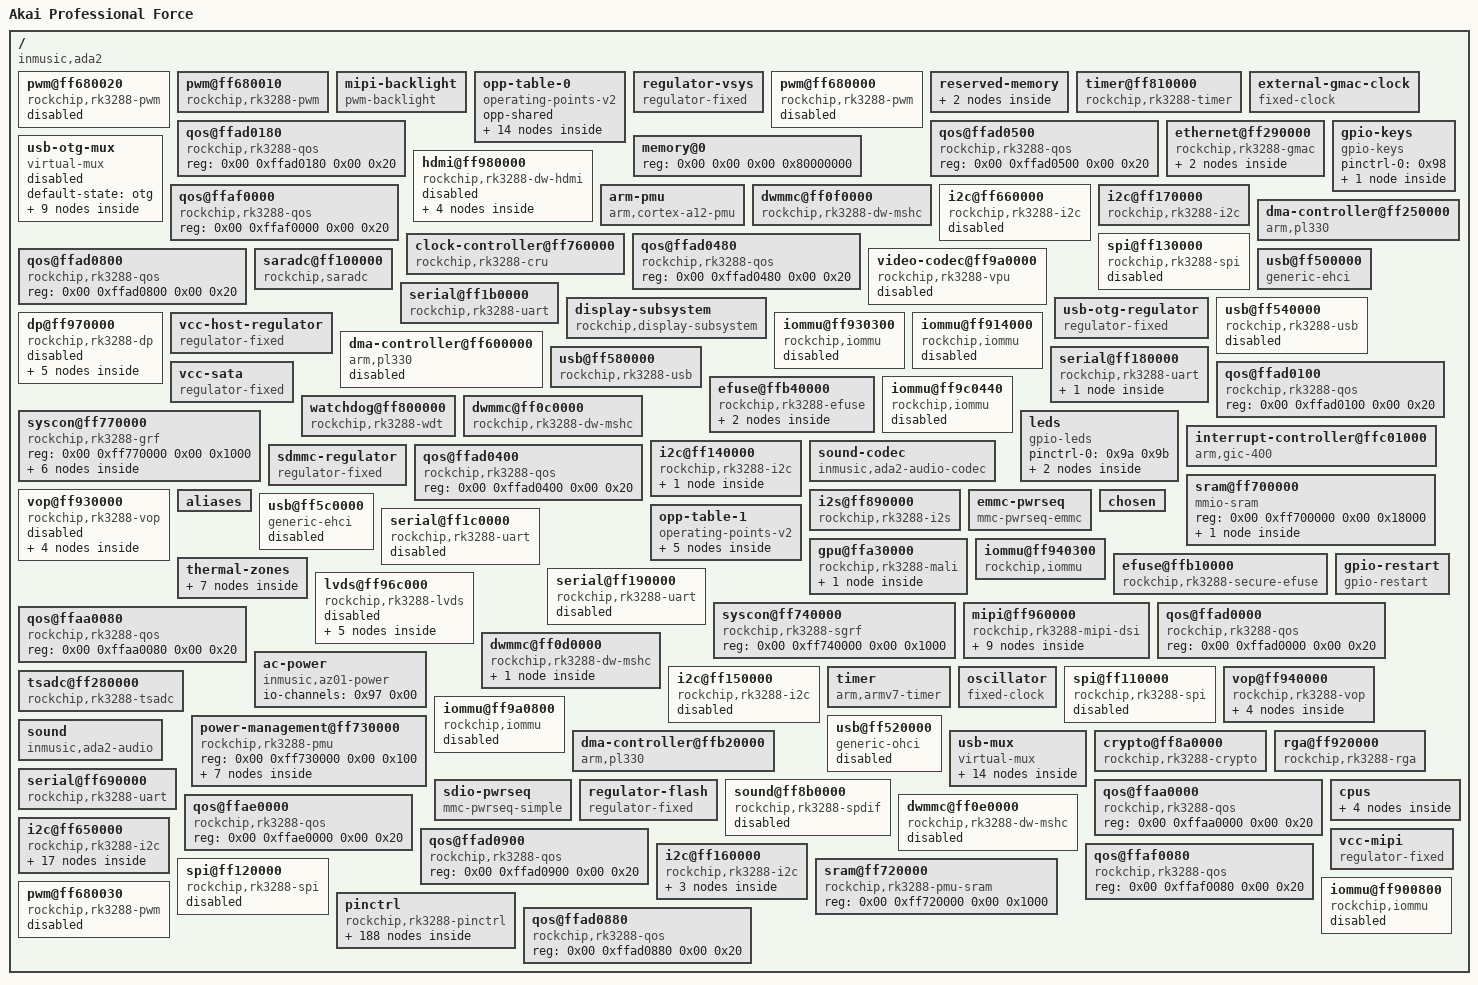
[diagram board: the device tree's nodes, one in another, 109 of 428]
/dts-v1/;

/ {
	inmusic,panel-rotation = <0x10e>;
	inmusic,product-code = "ADA2";
	compatible = "inmusic,ada2\0inmusic,az01\0rockchip,rk3288-c\0rockchip,rk3288";
	serial-number = "REDACTED";
	model = "Akai Professional Force";
	interrupt-parent = <0x01>;
	#address-cells = <0x02>;
	#size-cells = <0x02>;
	inmusic,az01-pcb-rev = "D";

	pwm@ff680020 {
		compatible = "rockchip,rk3288-pwm";
		clocks = <0x07 0x15f>;
		status = "disabled";
		reg = <0x00 0xff680020 0x00 0x10>;
		pinctrl-0 = <0x5d>;
		#pwm-cells = <0x03>;
		pinctrl-names = "default";
	};

	pwm@ff680010 {
		compatible = "rockchip,rk3288-pwm";
		clocks = <0x07 0x15f>;
		status = "okay";
		phandle = <0x9c>;
		reg = <0x00 0xff680010 0x00 0x10>;
		pinctrl-0 = <0x5c>;
		#pwm-cells = <0x03>;
		pinctrl-names = "default";
	};

	mipi-backlight {
		compatible = "pwm-backlight";
		default-brightness-level = <0x95>;
		brightness-levels = <0x00 0x01 0x02 0x03 0x04 0x05 0x06 0x07 0x08 0x09 0x0a 0x0b 0x0c 0x0d 0x0e 0x0f 0x10 0x11 0x12 0x13 0x14 0x15 0x16 0x17 0x18 0x19 0x1a 0x1b 0x1c 0x1d 0x1e 0x1f 0x20 0x21 0x22 0x23 0x24 0x25 0x26 0x27 0x28 0x29 0x2a 0x2b 0x2c 0x2d 0x2e 0x2f 0x30 0x31 0x32 0x33 0x34 0x35 0x36 0x37 0x38 0x39 0x3a 0x3b 0x3c 0x3d 0x3e 0x3f 0x40 0x41 0x42 0x43 0x44 0x45 0x46 0x47 0x48 0x49 0x4a 0x4b 0x4c 0x4d 0x4e 0x4f 0x50 0x51 0x52 0x53 0x54 0x55 0x56 0x57 0x58 0x59 0x5a 0x5b 0x5c 0x5d 0x5e 0x5f 0x60 0x61 0x62 0x63 0x64 0x65 0x66 0x67 0x68 0x69 0x6a 0x6b 0x6c 0x6d 0x6e 0x6f 0x70 0x71 0x72 0x73 0x74 0x75 0x76 0x77 0x78 0x79 0x7a 0x7b 0x7c 0x7d 0x7e 0x7f 0x80 0x81 0x82 0x83 0x84 0x85 0x86 0x87 0x88 0x89 0x8a 0x8b 0x8c 0x8d 0x8e 0x8f 0x90 0x91 0x92 0x93 0x94 0x95 0x96 0x97 0x98 0x99 0x9a 0x9b 0x9c 0x9d 0x9e 0x9f 0xa0 0xa1 0xa2 0xa3 0xa4 0xa5 0xa6 0xa7 0xa8 0xa9 0xaa 0xab 0xac 0xad 0xae 0xaf 0xb0 0xb1 0xb2 0xb3 0xb4 0xb5 0xb6 0xb7 0xb8 0xb9 0xba 0xbb 0xbc 0xbd 0xbe 0xbf 0xc0 0xc1 0xc2 0xc3 0xc4 0xc5 0xc6 0xc7 0xc8 0xc9 0xca 0xcb 0xcc 0xcd 0xce 0xcf 0xd0 0xd1 0xd2 0xd3 0xd4 0xd5 0xd6 0xd7 0xd8 0xd9 0xda 0xdb 0xdc 0xdd 0xde 0xdf 0xe0 0xe1 0xe2 0xe3 0xe4 0xe5 0xe6 0xe7 0xe8 0xe9 0xea 0xeb 0xec 0xed 0xee 0xef 0xf0 0xf1 0xf2 0xf3 0xf4 0xf5 0xf6 0xf7 0xf8 0xf9 0xfa 0xfb 0xfc 0xfd 0xfe 0xff>;
		phandle = <0x7e>;
		pwms = <0x9c 0x00 0xc350 0x00>;
		power-supply = <0x56>;
	};

	opp-table-0 {
		compatible = "operating-points-v2";
		phandle = <0x08>;
		opp-shared;

		opp-1512000000 {
			opp-microvolt = <0x13d620>;
			opp-hz = <0x00 0x5a1f4a00>;
		};

		opp-1416000000 {
			opp-microvolt = <0x124f80>;
			opp-hz = <0x00 0x54667200>;
		};

		opp-600000000 {
			opp-microvolt = <0xdbba0>;
			opp-hz = <0x00 0x23c34600>;
		};

		opp-1800000000 {
			opp-microvolt = <0x155cc0>;
			opp-hz = <0x00 0x6b49d200>;
		};

		opp-408000000 {
			opp-microvolt = <0xdbba0>;
			opp-hz = <0x00 0x18519600>;
		};

		opp-1704000000 {
			opp-microvolt = <0x149970>;
			opp-hz = <0x00 0x6590fa00>;
		};

		opp-126000000 {
			opp-microvolt = <0xdbba0>;
			opp-hz = <0x00 0x7829b80>;
			clock-latency-ns = <0x9c40>;
		};

		opp-1608000000 {
			opp-microvolt = <0x149970>;
			opp-hz = <0x00 0x5fd82200>;
		};

		opp-1200000000 {
			opp-microvolt = <0x10c8e0>;
			opp-hz = <0x00 0x47868c00>;
		};

		opp-1008000000 {
			opp-microvolt = <0x100590>;
			opp-hz = <0x00 0x3c14dc00>;
		};

		opp-816000000 {
			opp-microvolt = <0xf4240>;
			opp-hz = <0x00 0x30a32c00>;
		};

		opp-312000000 {
			opp-microvolt = <0xdbba0>;
			opp-hz = <0x00 0x1298be00>;
		};

		opp-696000000 {
			opp-microvolt = <0xe7ef0>;
			opp-hz = <0x00 0x297c1e00>;
		};

		opp-216000000 {
			opp-microvolt = <0xdbba0>;
			opp-hz = <0x00 0xcdfe600>;
		};
	};

	regulator-vsys {
		compatible = "regulator-fixed";
		regulator-boot-on;
		phandle = <0x56>;
		regulator-min-microvolt = <0x4c4b40>;
		regulator-max-microvolt = <0x4c4b40>;
		regulator-always-on;
		regulator-name = "vcc_sys";
	};

	pwm@ff680000 {
		compatible = "rockchip,rk3288-pwm";
		clocks = <0x07 0x15f>;
		status = "disabled";
		reg = <0x00 0xff680000 0x00 0x10>;
		pinctrl-0 = <0x5b>;
		#pwm-cells = <0x03>;
		pinctrl-names = "default";
	};

	reserved-memory {
		ranges;
		#address-cells = <0x02>;
		#size-cells = <0x02>;

		dma-unusable@fe000000 {
			reg = <0x00 0xfe000000 0x00 0x1000000>;
		};

		framebuffer {
			compatible = "rockchip,framebuffer-memory";
			status = "okay";
			phandle = <0x0d>;
			reg = <0x00 0x7f400000 0x00 0xc00000>;
		};
	};

	timer@ff810000 {
		compatible = "rockchip,rk3288-timer";
		clocks = <0x07 0x161 0x0a>;
		clock-names = "pclk\0timer";
		interrupts = <0x00 0x48 0x04>;
		reg = <0x00 0xff810000 0x00 0x20>;
	};

	external-gmac-clock {
		compatible = "fixed-clock";
		#clock-cells = <0x00>;
		phandle = <0x4b>;
		clock-output-names = "ext_gmac";
		clock-frequency = <0x7735940>;
	};

	qos@ffad0180 {
		compatible = "rockchip,rk3288-qos\0syscon";
		phandle = <0x62>;
		reg = <0x00 0xffad0180 0x00 0x20>;
	};

	qos@ffad0500 {
		compatible = "rockchip,rk3288-qos\0syscon";
		phandle = <0x5f>;
		reg = <0x00 0xffad0500 0x00 0x20>;
	};

	ethernet@ff290000 {
		rx_delay = <0x10>;
		phy-handle = <0x4c>;
		rockchip,grf = <0x4a>;
		assigned-clock-parents = <0x4b>;
		compatible = "rockchip,rk3288-gmac";
		clocks = <0x07 0x97 0x07 0x66 0x07 0x67 0x07 0x63 0x07 0x98 0x07 0xc4 0x07 0x15d>;
		local-mac-address = [REDACTED];
		resets = <0x07 0x42>;
		clock_in_out = "input";
		clock-names = "stmmaceth\0mac_clk_rx\0mac_clk_tx\0clk_mac_ref\0clk_mac_refout\0aclk_mac\0pclk_mac";
		phy-supply = <0x4d>;
		status = "okay";
		interrupts = <0x00 0x1b 0x04 0x00 0x1c 0x04>;
		assigned-clocks = <0x07 0x97>;
		tx_delay = <0x30>;
		reg = <0x00 0xff290000 0x00 0x10000>;
		phy-mode = "rgmii";
		pinctrl-0 = <0x4e 0x4f 0x50>;
		reset-names = "stmmaceth";
		interrupt-names = "macirq\0eth_wake_irq";
		pinctrl-names = "default";

		mdio {
			compatible = "snps,dwmac-mdio";
			#address-cells = <0x01>;
			#size-cells = <0x00>;

			ethernet-phy@1 {
				compatible = "ethernet-phy-ieee802.3-c22";
				reset-assert-us = <0x2710>;
				reset-deassert-us = <0x7530>;
				eee-broken-100tx;
				interrupt-parent = <0x51>;
				interrupts = <0x0f 0x08>;
				reset-gpios = <0x1f 0x08 0x01>;
				eee-broken-1000t;
				phandle = <0x4c>;
				reg = <0x01>;
			};
		};
	};

	usb-otg-mux {
		compatible = "virtual-mux";
		status = "disabled";
		default-state = "otg";

		state-peripheral {

			fragment@0 {
				target = <0x9d>;

				__overlay__ {
					status = "okay";
					dr_mode = "peripheral";
				};
			};
		};

		state-host {

			fragment@0 {
				target = <0x9d>;

				__overlay__ {
					status = "okay";
					dr_mode = "host";
				};
			};
		};

		state-otg {

			fragment@0 {
				target = <0x9d>;

				__overlay__ {
					status = "okay";
					dr_mode = "otg";
				};
			};
		};
	};

	memory@0 {
		device_type = "memory";
		reg = <0x00 0x00 0x00 0x80000000>;
	};

	hdmi@ff980000 {
		reg-io-width = <0x04>;
		rockchip,grf = <0x4a>;
		power-domains = <0x70 0x09>;
		compatible = "rockchip,rk3288-dw-hdmi";
		clocks = <0x07 0x168 0x07 0x6d 0x07 0x6e>;
		#sound-dai-cells = <0x00>;
		clock-names = "iahb\0isfr\0cec";
		status = "disabled";
		interrupts = <0x00 0x67 0x04>;
		reg = <0x00 0xff980000 0x00 0x20000>;
		ddc-i2c-bus = <0x86>;

		ports {
			#address-cells = <0x01>;
			#size-cells = <0x00>;

			port@1 {
				reg = <0x01>;
			};

			port@0 {
				#address-cells = <0x01>;
				#size-cells = <0x00>;
				reg = <0x00>;

				endpoint@0 {
					remote-endpoint = <0x87>;
					phandle = <0x72>;
					reg = <0x00>;
				};
			};
		};
	};

	qos@ffaf0000 {
		compatible = "rockchip,rk3288-qos\0syscon";
		phandle = <0x68>;
		reg = <0x00 0xffaf0000 0x00 0x20>;
	};

	arm-pmu {
		compatible = "arm,cortex-a12-pmu";
		interrupts = <0x00 0x97 0x04 0x00 0x98 0x04 0x00 0x99 0x04 0x00 0x9a 0x04>;
		interrupt-affinity = <0x02 0x03 0x04 0x05>;
	};

	dwmmc@ff0f0000 {
		cap-mmc-highspeed;
		compatible = "rockchip,rk3288-dw-mshc";
		clocks = <0x07 0x1cb 0x07 0x47 0x07 0x75 0x07 0x79>;
		mmc-ddr-1_8v;
		resets = <0x07 0x83>;
		clock-names = "biu\0ciu\0ciu-drive\0ciu-sample";
		fifo-depth = <0x100>;
		broken-cd;
		status = "okay";
		interrupts = <0x00 0x23 0x04>;
		disable-wp;
		bus-width = <0x08>;
		reg = <0x00 0xff0f0000 0x00 0x4000>;
		pinctrl-0 = <0x21 0x22 0x23>;
		reset-names = "reset";
		vmmc-supply = <0x1d>;
		mmc-pwrseq = <0x20>;
		non-removable;
		max-frequency = <0x8f0d180>;
		vqmmc-supply = <0x24>;
		pinctrl-names = "default";
	};

	i2c@ff660000 {
		compatible = "rockchip,rk3288-i2c";
		clocks = <0x07 0x14e>;
		clock-names = "i2c";
		status = "disabled";
		#address-cells = <0x01>;
		interrupts = <0x00 0x3d 0x04>;
		#size-cells = <0x00>;
		reg = <0x00 0xff660000 0x00 0x1000>;
		pinctrl-0 = <0x5a>;
		pinctrl-names = "default";
	};

	i2c@ff170000 {
		compatible = "rockchip,rk3288-i2c";
		clocks = <0x07 0x151>;
		clock-names = "i2c";
		status = "okay";
		#address-cells = <0x01>;
		interrupts = <0x00 0x41 0x04>;
		#size-cells = <0x00>;
		phandle = <0x86>;
		reg = <0x00 0xff170000 0x00 0x1000>;
		pinctrl-0 = <0x39>;
		pinctrl-names = "default";
	};

	gpio-keys {
		compatible = "gpio-keys";
		#address-cells = <0x01>;
		#size-cells = <0x00>;
		pinctrl-0 = <0x98>;
		pinctrl-names = "default";

		power {
			gpios = <0x58 0x05 0x01>;
			wakeup-source;
			debounce-interval = <0x14>;
			label = "Power";
			linux,code = <0x74>;
		};
	};

	clock-controller@ff760000 {
		rockchip,grf = <0x4a>;
		assigned-clock-parents = <0x07 0x04 0x07 0x05>;
		compatible = "rockchip,rk3288-cru";
		clocks = <0x0a>;
		#reset-cells = <0x01>;
		clock-names = "xin24m";
		assigned-clock-rates = <0x00 0x00 0x2367b880 0x17d78400 0x00 0x11e1a300 0x8f0d180 0x47868c0 0x11e1a300 0x8f0d180 0x47868c0>;
		#clock-cells = <0x01>;
		assigned-clocks = <0x07 0xbe 0x07 0xbf 0x07 0x04 0x07 0x03 0x07 0x05 0x07 0xd1 0x07 0x1dd 0x07 0x16a 0x07 0xd2 0x07 0x1de 0x07 0x16b>;
		phandle = <0x07>;
		reg = <0x00 0xff760000 0x00 0x1000>;
	};

	dma-controller@ff250000 {
		#dma-cells = <0x01>;
		compatible = "arm,pl330\0arm,primecell";
		clocks = <0x07 0xc2>;
		clock-names = "apb_pclk";
		arm,pl330-broken-no-flushp;
		interrupts = <0x00 0x02 0x04 0x00 0x03 0x04>;
		arm,pl330-periph-burst;
		phandle = <0x25>;
		reg = <0x00 0xff250000 0x00 0x4000>;
	};

	qos@ffad0480 {
		compatible = "rockchip,rk3288-qos\0syscon";
		phandle = <0x64>;
		reg = <0x00 0xffad0480 0x00 0x20>;
	};

	qos@ffad0800 {
		compatible = "rockchip,rk3288-qos\0syscon";
		phandle = <0x65>;
		reg = <0x00 0xffad0800 0x00 0x20>;
	};

	spi@ff130000 {
		compatible = "rockchip,rk3288-spi\0rockchip,rk3066-spi";
		clocks = <0x07 0x43 0x07 0x154>;
		clock-names = "spiclk\0apb_pclk";
		status = "disabled";
		#address-cells = <0x01>;
		interrupts = <0x00 0x2e 0x04>;
		#size-cells = <0x00>;
		dma-names = "tx\0rx";
		reg = <0x00 0xff130000 0x00 0x1000>;
		pinctrl-0 = <0x2e 0x2f 0x30 0x31>;
		dmas = <0x25 0x0f 0x25 0x10>;
		pinctrl-names = "default";
	};

	saradc@ff100000 {
		compatible = "rockchip,saradc";
		clocks = <0x07 0x49 0x07 0x15b>;
		resets = <0x07 0x57>;
		#io-channel-cells = <0x01>;
		clock-names = "saradc\0apb_pclk";
		vref-supply = <0x1e>;
		status = "okay";
		interrupts = <0x00 0x24 0x04>;
		phandle = <0x97>;
		reg = <0x00 0xff100000 0x00 0x100>;
		reset-names = "saradc-apb";
	};

	video-codec@ff9a0000 {
		power-domains = <0x70 0x0c>;
		compatible = "rockchip,rk3288-vpu";
		clocks = <0x07 0xd0 0x07 0x1dc>;
		clock-names = "aclk\0hclk";
		status = "disabled";
		interrupts = <0x00 0x09 0x04 0x00 0x0a 0x04>;
		reg = <0x00 0xff9a0000 0x00 0x800>;
		iommus = <0x88>;
		interrupt-names = "vepu\0vdpu";
	};

	usb@ff500000 {
		compatible = "generic-ehci";
		clocks = <0x07 0x1c2>;
		resets = <0x07 0x48>;
		phy-names = "usb";
		status = "okay";
		interrupts = <0x00 0x18 0x04>;
		phys = <0x52>;
		reg = <0x00 0xff500000 0x00 0x100>;
		reset-names = "usbhost";
	};

	serial@ff1b0000 {
		reg-io-width = <0x04>;
		compatible = "rockchip,rk3288-uart\0snps,dw-apb-uart";
		clocks = <0x07 0x50 0x07 0x158>;
		clock-names = "baudclk\0apb_pclk";
		status = "okay";
		interrupts = <0x00 0x3a 0x04>;
		dma-names = "tx\0rx";
		reg = <0x00 0xff1b0000 0x00 0x100>;
		pinctrl-0 = <0x45>;
		dmas = <0x25 0x07 0x25 0x08>;
		reg-shift = <0x02>;
		pinctrl-names = "default";
	};

	display-subsystem {
		compatible = "rockchip,display-subsystem";
		ports = <0x0b 0x0c>;
		memory-region = <0x0d>;
	};

	usb-otg-regulator {
		compatible = "regulator-fixed";
		enable-active-high;
		gpio = <0x58 0x0c 0x00>;
		regulator-min-microvolt = <0x4c4b40>;
		regulator-max-microvolt = <0x4c4b40>;
		pinctrl-0 = <0xa3>;
		regulator-always-on;
		regulator-name = "vcc_otg_5v";
		pinctrl-names = "default";
	};

	usb@ff540000 {
		compatible = "rockchip,rk3288-usb\0rockchip,rk3066-usb\0snps,dwc2";
		clocks = <0x07 0x1c3>;
		snps,reset-phy-on-wake;
		clock-names = "otg";
		phy-names = "usb2-phy";
		status = "disabled";
		interrupts = <0x00 0x19 0x04>;
		phys = <0x53>;
		reg = <0x00 0xff540000 0x00 0x40000>;
		dr_mode = "host";
	};

	dp@ff970000 {
		rockchip,grf = <0x4a>;
		power-domains = <0x70 0x09>;
		compatible = "rockchip,rk3288-dp";
		clocks = <0x07 0x69 0x07 0x163>;
		resets = <0x07 0x6f>;
		clock-names = "dp\0pclk";
		phy-names = "dp";
		status = "disabled";
		interrupts = <0x00 0x62 0x04>;
		phys = <0x83>;
		reg = <0x00 0xff970000 0x00 0x4000>;
		reset-names = "dp";

		ports {
			#address-cells = <0x01>;
			#size-cells = <0x00>;

			port@1 {
				reg = <0x01>;
			};

			port@0 {
				#address-cells = <0x01>;
				#size-cells = <0x00>;
				reg = <0x00>;

				endpoint@1 {
					remote-endpoint = <0x85>;
					phandle = <0x76>;
					reg = <0x01>;
				};

				endpoint@0 {
					remote-endpoint = <0x84>;
					phandle = <0x73>;
					reg = <0x00>;
				};
			};
		};
	};

	vcc-host-regulator {
		compatible = "regulator-fixed";
		enable-active-high;
		gpio = <0x58 0x0e 0x00>;
		pinctrl-0 = <0xa2>;
		regulator-always-on;
		regulator-name = "vcc_host";
		pinctrl-names = "default";
	};

	iommu@ff930300 {
		power-domains = <0x70 0x09>;
		compatible = "rockchip,iommu";
		clocks = <0x07 0xc5 0x07 0x1d1>;
		#iommu-cells = <0x00>;
		clock-names = "aclk\0iface";
		status = "disabled";
		interrupts = <0x00 0x0f 0x04>;
		phandle = <0x71>;
		reg = <0x00 0xff930300 0x00 0x100>;
	};

	dma-controller@ff600000 {
		#dma-cells = <0x01>;
		compatible = "arm,pl330\0arm,primecell";
		clocks = <0x07 0xc1>;
		clock-names = "apb_pclk";
		arm,pl330-broken-no-flushp;
		status = "disabled";
		interrupts = <0x00 0x00 0x04 0x00 0x01 0x04>;
		arm,pl330-periph-burst;
		reg = <0x00 0xff600000 0x00 0x4000>;
	};

	usb@ff580000 {
		compatible = "rockchip,rk3288-usb\0rockchip,rk3066-usb\0snps,dwc2";
		clocks = <0x07 0x1c1>;
		clock-names = "otg";
		phy-names = "usb2-phy";
		g-rx-fifo-size = <0x113>;
		status = "okay";
		interrupts = <0x00 0x17 0x04>;
		phandle = <0x9d>;
		phys = <0x54>;
		reg = <0x00 0xff580000 0x00 0x40000>;
		dr_mode = "otg";
		g-tx-fifo-size = <0x100 0x80 0x80 0x40 0x40 0x20>;
		g-np-tx-fifo-size = <0x10>;
	};

	iommu@ff914000 {
		compatible = "rockchip,iommu";
		clocks = <0x07 0xcd 0x07 0x1d5>;
		#iommu-cells = <0x00>;
		rockchip,disable-mmu-reset;
		clock-names = "aclk\0iface";
		status = "disabled";
		interrupts = <0x00 0x0e 0x04>;
		reg = <0x00 0xff914000 0x00 0x100 0x00 0xff915000 0x00 0x100>;
	};

	serial@ff180000 {
		reg-io-width = <0x04>;
		compatible = "rockchip,rk3288-uart\0snps,dw-apb-uart";
		clocks = <0x07 0x4d 0x07 0x155>;
		clock-names = "baudclk\0apb_pclk";
		status = "okay";
		interrupts = <0x00 0x37 0x04>;
		assigned-clock-rates = <0x16e3600>;
		dma-names = "tx\0rx";
		assigned-clocks = <0x07 0x4d>;
		reg = <0x00 0xff180000 0x00 0x100>;
		pinctrl-0 = <0x3a 0x3b 0x3c>;
		dmas = <0x25 0x01 0x25 0x02>;
		reg-shift = <0x02>;
		pinctrl-names = "default";

		bluetooth {
			compatible = "brcm,bcm43438-bt";
			shutdown-gpios = <0x1f 0x1d 0x00>;
			clocks = <0x3d>;
			max-speed = <0x16e360>;
			device-wakeup-gpios = <0x1f 0x1a 0x00>;
			pinctrl-0 = <0x3e 0x3f 0x40>;
			pinctrl-names = "default";
		};
	};

	vcc-sata {
		compatible = "regulator-fixed";
		enable-active-high;
		gpio = <0x58 0x0d 0x00>;
		regulator-min-microvolt = <0x4c4b40>;
		vin-supply = <0x56>;
		regulator-max-microvolt = <0x4c4b40>;
		pinctrl-0 = <0xa0>;
		regulator-always-on;
		regulator-name = "vcc_sata";
		pinctrl-names = "default";
	};

	qos@ffad0100 {
		compatible = "rockchip,rk3288-qos\0syscon";
		phandle = <0x61>;
		reg = <0x00 0xffad0100 0x00 0x20>;
	};

	efuse@ffb40000 {
		compatible = "rockchip,rk3288-efuse";
		clocks = <0x07 0x171>;
		clock-names = "pclk_efuse";
		#address-cells = <0x01>;
		#size-cells = <0x01>;
		reg = <0x00 0xffb40000 0x00 0x20>;

		cpu-id@7 {
			reg = <0x07 0x10>;
		};

		cpu_leakage@17 {
			reg = <0x17 0x01>;
		};
	};

	iommu@ff9c0440 {
		compatible = "rockchip,iommu";
		clocks = <0x07 0xcf 0x07 0x1db>;
		#iommu-cells = <0x00>;
		clock-names = "aclk\0iface";
		status = "disabled";
		interrupts = <0x00 0x6f 0x04>;
		reg = <0x00 0xff9c0440 0x00 0x40 0x00 0xff9c0480 0x00 0x40>;
	};

	watchdog@ff800000 {
		compatible = "rockchip,rk3288-wdt\0snps,dw-wdt";
		clocks = <0x07 0x170>;
		status = "okay";
		interrupts = <0x00 0x4f 0x04>;
		reg = <0x00 0xff800000 0x00 0x100>;
	};

	syscon@ff770000 {
		compatible = "rockchip,rk3288-grf\0syscon\0simple-mfd";
		phandle = <0x4a>;
		reg = <0x00 0xff770000 0x00 0x1000>;

		edp-phy {
			compatible = "rockchip,rk3288-dp-phy";
			clocks = <0x07 0x68>;
			clock-names = "24m";
			status = "disabled";
			phandle = <0x83>;
			#phy-cells = <0x00>;
		};

		usbphy {
			compatible = "rockchip,rk3288-usb-phy";
			status = "okay";
			#address-cells = <0x01>;
			#size-cells = <0x00>;

			usb-phy@348 {
				clocks = <0x07 0x5f>;
				resets = <0x07 0x8b>;
				clock-names = "phyclk";
				#clock-cells = <0x00>;
				phandle = <0x53>;
				reg = <0x348>;
				reset-names = "phy-reset";
				#phy-cells = <0x00>;
			};

			usb-phy@334 {
				clocks = <0x07 0x5e>;
				resets = <0x07 0x88>;
				clock-names = "phyclk";
				#clock-cells = <0x00>;
				phandle = <0x52>;
				reg = <0x334>;
				reset-names = "phy-reset";
				#phy-cells = <0x00>;
			};

			usb-phy@320 {
				clocks = <0x07 0x5d>;
				resets = <0x07 0x85>;
				clock-names = "phyclk";
				#clock-cells = <0x00>;
				phandle = <0x54>;
				reg = <0x320>;
				reset-names = "phy-reset";
				#phy-cells = <0x00>;
			};
		};

		io-domains {
			compatible = "rockchip,rk3288-io-voltage-domain";
			sdcard-supply = <0x17>;
			gpio1830-supply = <0x1d>;
			audio-supply = <0x1d>;
			lcdc-supply = <0x1d>;
			status = "okay";
			dvp-supply = <0x1d>;
			flash1-supply = <0x4d>;
			gpio30-supply = <0x4d>;
			flash0-supply = <0x24>;
			bb-supply = <0x1e>;
			wifi-supply = <0x1e>;
		};
	};

	dwmmc@ff0c0000 {
		compatible = "rockchip,rk3288-dw-mshc";
		clocks = <0x07 0x1c8 0x07 0x44 0x07 0x72 0x07 0x76>;
		num-slots = <0x01>;
		resets = <0x07 0x80>;
		pinctrl-1 = <0x15 0x14>;
		clock-names = "biu\0ciu\0ciu-drive\0ciu-sample";
		fifo-depth = <0x100>;
		broken-cd;
		status = "okay";
		interrupts = <0x00 0x20 0x04>;
		disable-wp;
		bus-width = <0x04>;
		no-prescan-powerup;
		sd-uhs-sdr12;
		reg = <0x00 0xff0c0000 0x00 0x4000>;
		rockchip,default-sample-phase = <0xb4>;
		pinctrl-0 = <0x0e 0x0f 0x10 0x11 0x12 0x13 0x14>;
		card-detect-delay = <0xc8>;
		reset-names = "reset";
		vmmc-supply = <0x16>;
		max-frequency = <0x8f0d180>;
		vqmmc-supply = <0x17>;
		pinctrl-names = "default\0pwroff";
	};

	leds {
		compatible = "gpio-leds";
		pinctrl-0 = <0x9a 0x9b>;
		pinctrl-names = "default";

		led2 {
			gpios = <0x58 0x0b 0x01>;
			label = "az01:red:usr2";
			linux,default-trigger = "none";
		};

		led1 {
			gpios = <0x33 0x0f 0x01>;
			label = "az01:red:usr1";
			linux,default-trigger = "heartbeat";
		};
	};

	interrupt-controller@ffc01000 {
		compatible = "arm,gic-400";
		#interrupt-cells = <0x03>;
		#address-cells = <0x00>;
		interrupts = <0x01 0x09 0xf04>;
		phandle = <0x01>;
		reg = <0x00 0xffc01000 0x00 0x1000 0x00 0xffc02000 0x00 0x2000 0x00 0xffc04000 0x00 0x2000 0x00 0xffc06000 0x00 0x2000>;
		interrupt-controller;
	};

	i2c@ff140000 {
		compatible = "rockchip,rk3288-i2c";
		clocks = <0x07 0x14d>;
		clock-names = "i2c";
		status = "okay";
		#address-cells = <0x01>;
		interrupts = <0x00 0x3e 0x04>;
		#size-cells = <0x00>;
		reg = <0x00 0xff140000 0x00 0x1000>;
		pinctrl-0 = <0x32>;
		pinctrl-names = "default";

		usb5537@2d {
			smsc,config-file = [43 46 47 42 14 40 10 06 40 08 04 40 18 26 40 18 16 40 00 03 40 00 03 40 00 03 40 00 03 40 00 03 40 00 03 40 00 03 40 10 06 40 08 04 40 00 03 40 00 03 40 00 03 40 00 03 40 18 26 40 18 16 40 80 03 30 00 e8 09 40 50 30 13 11 09 30 16 00 22 41 00 6b 00 61 00 69 00 20 00 50 00 72 00 6f 00 66 00 65 00 73 00 73 00 69 00 6f 00 6e 00 61 00 6c 00 30 54 00 12 46 00 6f 00 72 00 63 00 65 00 20 00 48 00 75 00 62 00 3c 00 23 3c 04 23 3c 08 23 3c 0c 03 3c 10 03 3c 14 03 3c 18 03 50 48 e8 09 40 60 50 4e 02 03 50 18 24 50 f4 24 50 1c 14 51 34 14 50 f6 00 22 41 00 6b 00 61 00 69 00 20 00 50 00 72 00 6f 00 66 00 65 00 73 00 73 00 69 00 6f 00 6e 00 61 00 6c 00 51 36 00 12 46 00 6f 00 72 00 63 00 65 00 20 00 48 00 75 00 62 00 52 43 20];
			compatible = "smsc,usb5537b";
			status = "okay";
			reset-gpios = <0x33 0x02 0x00>;
			phandle = <0xa5>;
			reg = <0x2d>;
			pinctrl-0 = <0x34 0xa6>;
			pinctrl-names = "default";
		};
	};

	sound-codec {
		compatible = "inmusic,ada2-audio-codec";
		clocks = <0x07 0x71>;
		#sound-dai-cells = <0x00>;
		mute-gpios = <0x7d 0x02 0x00>;
		reset-gpios = <0x7d 0x00 0x01>;
		phandle = <0xaa>;
		pinctrl-0 = <0xab 0xac 0xad>;
		enable-gpios = <0x7d 0x01 0x00>;
		pinctrl-names = "default";
	};

	sdmmc-regulator {
		compatible = "regulator-fixed";
		gpio = <0x33 0x0b 0x01>;
		off-on-delay-us = <0x7a120>;
		status = "okay";
		phandle = <0x16>;
		regulator-min-microvolt = <0x325aa0>;
		vin-supply = <0x1d>;
		regulator-max-microvolt = <0x325aa0>;
		pinctrl-0 = <0xa1>;
		regulator-name = "vcc_sd";
		pinctrl-names = "default";
	};

	qos@ffad0400 {
		compatible = "rockchip,rk3288-qos\0syscon";
		phandle = <0x63>;
		reg = <0x00 0xffad0400 0x00 0x20>;
	};

	sram@ff700000 {
		compatible = "mmio-sram";
		ranges = <0x00 0x00 0xff700000 0x18000>;
		#address-cells = <0x01>;
		#size-cells = <0x01>;
		reg = <0x00 0xff700000 0x00 0x18000>;

		smp-sram@0 {
			compatible = "rockchip,rk3066-smp-sram";
			reg = <0x00 0x10>;
		};
	};

	vop@ff930000 {
		power-domains = <0x70 0x09>;
		compatible = "rockchip,rk3288-vop";
		clocks = <0x07 0xc5 0x07 0xbe 0x07 0x1d1>;
		resets = <0x07 0x64 0x07 0x65 0x07 0x66>;
		clock-names = "aclk_vop\0dclk_vop\0hclk_vop";
		status = "disabled";
		interrupts = <0x00 0x0f 0x04>;
		reg = <0x00 0xff930000 0x00 0x19c 0x00 0xff931000 0x00 0x1000>;
		iommus = <0x71>;
		reset-names = "axi\0ahb\0dclk";

		port {
			#address-cells = <0x01>;
			#size-cells = <0x00>;
			phandle = <0x0c>;

			endpoint@1 {
				remote-endpoint = <0x73>;
				phandle = <0x84>;
				reg = <0x01>;
			};

			endpoint@0 {
				remote-endpoint = <0x72>;
				phandle = <0x87>;
				reg = <0x00>;
			};

			endpoint@3 {
				remote-endpoint = <0x74>;
				phandle = <0x81>;
				reg = <0x03>;
			};
		};
	};

	i2s@ff890000 {
		compatible = "rockchip,rk3288-i2s\0rockchip,rk3066-i2s";
		clocks = <0x07 0x52 0x07 0x1ce>;
		#sound-dai-cells = <0x00>;
		rockchip,playback-channels = <0x08>;
		clock-names = "i2s_clk\0i2s_hclk";
		status = "okay";
		interrupts = <0x00 0x35 0x04>;
		dma-names = "tx\0rx";
		phandle = <0xa9>;
		reg = <0x00 0xff890000 0x00 0x10000>;
		rockchip,capture-channels = <0x02>;
		pinctrl-0 = <0x6f>;
		dmas = <0x6d 0x00 0x6d 0x01>;
		pinctrl-names = "default";
	};

	emmc-pwrseq {
		compatible = "mmc-pwrseq-emmc";
		reset-gpios = <0x51 0x09 0x01>;
		phandle = <0x20>;
		pinctrl-0 = <0x96>;
		pinctrl-names = "default";
	};

	aliases {
		i2c3 = "/i2c@ff150000";
		gpio2 = "/pinctrl/gpio@ff790000";
		spi2 = "/spi@ff130000";
		i2c1 = "/i2c@ff140000";
		mmc3 = "/dwmmc@ff0e0000";
		gpio0 = "/pinctrl/gpio@ff750000";
		spi0 = "/spi@ff110000";
		mmc1 = "/dwmmc@ff0c0000";
		gpio7 = "/pinctrl/gpio@ff7e0000";
		ethernet0 = "/ethernet@ff290000";
		serial3 = "/serial@ff1b0000";
		gpio5 = "/pinctrl/gpio@ff7c0000";
		serial1 = "/serial@ff190000";
		i2c4 = "/i2c@ff160000";
		gpio3 = "/pinctrl/gpio@ff7a0000";
		i2c2 = "/i2c@ff660000";
		gpio1 = "/pinctrl/gpio@ff780000";
		spi1 = "/spi@ff120000";
		i2c0 = "/i2c@ff650000";
		mmc2 = "/dwmmc@ff0d0000";
		gpio8 = "/pinctrl/gpio@ff7f0000";
		mmc0 = "/dwmmc@ff0f0000";
		serial4 = "/serial@ff1c0000";
		gpio6 = "/pinctrl/gpio@ff7d0000";
		serial2 = "/serial@ff690000";
		i2c5 = "/i2c@ff170000";
		gpio4 = "/pinctrl/gpio@ff7b0000";
		serial0 = "/serial@ff180000";
	};

	chosen {
		inmusic,internal-sd-fitted;
		stdout-path = "serial2:115200n8";
		bootargs = "root=PARTUUID=24d1deac-3434-1a4e-98d1-68ee2945a5f1 rootwait ro console=ttyS2,115200 rfkill.default_state=0 systemd.mask=no-reserved-blocks@dev-mmcblk1p1.service fsck.repair=yes";
		inmusic,acvs-emmc-synths;
	};

	opp-table-1 {
		compatible = "operating-points-v2";
		phandle = <0x89>;

		opp-200000000 {
			opp-microvolt = <0xe7ef0>;
			opp-hz = <0x00 0xbebc200>;
		};

		opp-600000000 {
			opp-microvolt = <0x13d620>;
			opp-hz = <0x00 0x23c34600>;
		};

		opp-300000000 {
			opp-microvolt = <0xf4240>;
			opp-hz = <0x00 0x11e1a300>;
		};

		opp-400000000 {
			opp-microvolt = <0x10c8e0>;
			opp-hz = <0x00 0x17d78400>;
		};

		opp-100000000 {
			opp-microvolt = <0xe7ef0>;
			opp-hz = <0x00 0x5f5e100>;
		};
	};

	usb@ff5c0000 {
		compatible = "generic-ehci";
		clocks = <0x07 0x1c4>;
		status = "disabled";
		interrupts = <0x00 0x1a 0x04>;
		reg = <0x00 0xff5c0000 0x00 0x100>;
	};

	serial@ff1c0000 {
		reg-io-width = <0x04>;
		compatible = "rockchip,rk3288-uart\0snps,dw-apb-uart";
		clocks = <0x07 0x51 0x07 0x159>;
		clock-names = "baudclk\0apb_pclk";
		status = "disabled";
		interrupts = <0x00 0x3b 0x04>;
		dma-names = "tx\0rx";
		reg = <0x00 0xff1c0000 0x00 0x100>;
		pinctrl-0 = <0x46>;
		dmas = <0x25 0x09 0x25 0x0a>;
		reg-shift = <0x02>;
		pinctrl-names = "default";
	};

	gpu@ffa30000 {
		power-domains = <0x70 0x0d>;
		compatible = "rockchip,rk3288-mali\0arm,mali-t760";
		clocks = <0x07 0xc0>;
		downdifferential = <0x0a>;
		status = "okay";
		interrupts = <0x00 0x06 0x04 0x00 0x07 0x04 0x00 0x08 0x04>;
		upthreshold = <0x4b>;
		operating-points-v2 = <0x89>;
		dynamic-power-coefficient = <0x2dd>;
		mali-supply = <0x8a>;
		reg = <0x00 0xffa30000 0x00 0x10000>;
		#cooling-cells = <0x02>;
		interrupt-names = "job\0mmu\0gpu";

		power_model {
			dynamic-coefficient = <0x2dd>;
			compatible = "arm,mali-simple-power-model";
			static-coefficient = <0x64578>;
			thermal-zone = "gpu-thermal";
			ts = <0x7d00 0x125c 0xffffffb0 0x02>;
		};
	};

	iommu@ff940300 {
		power-domains = <0x70 0x09>;
		compatible = "rockchip,iommu";
		clocks = <0x07 0xc6 0x07 0x1d2>;
		#iommu-cells = <0x00>;
		clock-names = "aclk\0iface";
		status = "okay";
		interrupts = <0x00 0x10 0x04>;
		phandle = <0x75>;
		reg = <0x00 0xff940300 0x00 0x100>;
	};

	efuse@ffb10000 {
		compatible = "rockchip,rk3288-secure-efuse";
		clocks = <0x07 0x172>;
		clock-names = "pclk_efuse";
		#address-cells = <0x01>;
		#size-cells = <0x01>;
		rockchip,efuse-size = <0x80>;
		reg = <0x00 0xffb10000 0x00 0x20>;
	};

	thermal-zones {

		gpu-thermal {
			thermal-sensors = <0x47 0x02>;
			polling-delay = <0x1388>;
			polling-delay-passive = <0x64>;

			trips {

				gpu_crit {
					hysteresis = <0x7d0>;
					temperature = <0x1b968>;
					type = "critical";
				};
			};
		};

		reserve-thermal {
			thermal-sensors = <0x47 0x00>;
			polling-delay = <0x1388>;
			polling-delay-passive = <0x3e8>;
		};

		cpu-thermal {
			thermal-sensors = <0x47 0x01>;
			polling-delay = <0x1388>;
			polling-delay-passive = <0x64>;

			trips {

				cpu_crit {
					hysteresis = <0x7d0>;
					temperature = <0x1b968>;
					type = "critical";
				};
			};
		};
	};

	serial@ff190000 {
		reg-io-width = <0x04>;
		compatible = "rockchip,rk3288-uart\0snps,dw-apb-uart";
		clocks = <0x07 0x4e 0x07 0x156>;
		clock-names = "baudclk\0apb_pclk";
		status = "disabled";
		interrupts = <0x00 0x38 0x04>;
		dma-names = "tx\0rx";
		reg = <0x00 0xff190000 0x00 0x100>;
		pinctrl-0 = <0x41 0x42 0x43>;
		dmas = <0x25 0x03 0x25 0x04>;
		reg-shift = <0x02>;
		pinctrl-names = "default";
	};

	gpio-restart {
		gpios = <0x58 0x09 0x00>;
		compatible = "gpio-restart";
		active-delay = <0x01>;
		pinctrl-0 = <0x99>;
		priority = <0xff>;
		wait-delay = <0x32>;
		inactive-delay = <0x01>;
		pinctrl-names = "default";
	};

	lvds@ff96c000 {
		rockchip,grf = <0x4a>;
		power-domains = <0x70 0x09>;
		compatible = "rockchip,rk3288-lvds";
		clocks = <0x07 0x167>;
		clock-names = "pclk_lvds";
		status = "disabled";
		reg = <0x00 0xff96c000 0x00 0x4000>;
		pinctrl-0 = <0x80>;
		pinctrl-names = "lcdc";

		ports {
			#address-cells = <0x01>;
			#size-cells = <0x00>;

			port@1 {
				reg = <0x01>;
			};

			port@0 {
				#address-cells = <0x01>;
				#size-cells = <0x00>;
				reg = <0x00>;

				endpoint@1 {
					remote-endpoint = <0x82>;
					phandle = <0x78>;
					reg = <0x01>;
				};

				endpoint@0 {
					remote-endpoint = <0x81>;
					phandle = <0x74>;
					reg = <0x00>;
				};
			};
		};
	};

	syscon@ff740000 {
		compatible = "rockchip,rk3288-sgrf\0syscon";
		reg = <0x00 0xff740000 0x00 0x1000>;
	};

	mipi@ff960000 {
		rockchip,grf = <0x4a>;
		power-domains = <0x70 0x09>;
		compatible = "rockchip,rk3288-mipi-dsi\0snps,dw-mipi-dsi";
		clocks = <0x07 0x7e 0x07 0x164>;
		resets = <0x07 0x73>;
		clock-names = "ref\0pclk";
		status = "okay";
		#address-cells = <0x01>;
		interrupts = <0x00 0x13 0x04>;
		#size-cells = <0x00>;
		reg = <0x00 0xff960000 0x00 0x4000>;
		reset-names = "apb";

		ports {
			#address-cells = <0x01>;
			#size-cells = <0x00>;

			port@1 {
				reg = <0x01>;

				endpoint {
					remote-endpoint = <0x7a>;
					phandle = <0x7f>;
				};
			};

			port@0 {
				#address-cells = <0x01>;
				#size-cells = <0x00>;
				reg = <0x00>;

				endpoint@1 {
					remote-endpoint = <0x79>;
					phandle = <0x77>;
					reg = <0x01>;
				};
			};
		};

		panel@0 {
			compatible = "urt,umo-p076md-t";
			rotation = <0x10e>;
			reset-gpios = <0x7d 0x07 0x00>;
			reg = <0x00>;
			pinctrl-0 = <0x7b>;
			backlight = <0x7e>;
			power-supply = <0x7c>;
			pinctrl-names = "default";

			ports {
				#address-cells = <0x01>;
				#size-cells = <0x00>;

				port@0 {
					reg = <0x00>;

					endpoint {
						remote-endpoint = <0x7f>;
						phandle = <0x7a>;
					};
				};
			};
		};
	};

	qos@ffad0000 {
		compatible = "rockchip,rk3288-qos\0syscon";
		phandle = <0x60>;
		reg = <0x00 0xffad0000 0x00 0x20>;
	};

	qos@ffaa0080 {
		compatible = "rockchip,rk3288-qos\0syscon";
		phandle = <0x6c>;
		reg = <0x00 0xffaa0080 0x00 0x20>;
	};

	dwmmc@ff0d0000 {
		post-power-on-delay-ms = <0x96>;
		compatible = "rockchip,rk3288-dw-mshc";
		clocks = <0x07 0x1c9 0x07 0x45 0x07 0x73 0x07 0x77>;
		num-slots = <0x01>;
		cap-sd-highspeed;
		resets = <0x07 0x81>;
		cap-sdio-irq;
		clock-names = "biu\0ciu\0ciu-drive\0ciu-sample";
		fifo-depth = <0x100>;
		broken-cd;
		status = "okay";
		#address-cells = <0x01>;
		interrupts = <0x00 0x21 0x04>;
		disable-wp;
		bus-width = <0x04>;
		#size-cells = <0x00>;
		sd-uhs-sdr12;
		reg = <0x00 0xff0d0000 0x00 0x4000>;
		pinctrl-0 = <0x19 0x1a 0x1b 0x1c>;
		reset-names = "reset";
		vmmc-supply = <0x1d>;
		mmc-pwrseq = <0x18>;
		non-removable;
		max-frequency = <0x8f0d180>;
		vqmmc-supply = <0x1e>;
		pinctrl-names = "default";

		bcrmf@0 {
			compatible = "brcm,bcm4329-fmac";
			status = "okay";
			interrupt-parent = <0x1f>;
			interrupts = <0x1e 0x02>;
			reg = <0x00>;
			interrupt-names = "host-wake";
		};
	};

	ac-power {
		io-channels = <0x97 0x00>;
		compatible = "inmusic,az01-power";
	};

	i2c@ff150000 {
		compatible = "rockchip,rk3288-i2c";
		clocks = <0x07 0x14f>;
		clock-names = "i2c";
		status = "disabled";
		#address-cells = <0x01>;
		interrupts = <0x00 0x3f 0x04>;
		#size-cells = <0x00>;
		reg = <0x00 0xff150000 0x00 0x1000>;
		pinctrl-0 = <0x35>;
		pinctrl-names = "default";
	};

	timer {
		arm,no-tick-in-suspend;
		compatible = "arm,armv7-timer";
		interrupts = <0x01 0x0d 0xf04 0x01 0x0e 0xf04 0x01 0x0b 0xf04 0x01 0x0a 0xf04>;
		arm,cpu-registers-not-fw-configured;
		clock-frequency = <0x16e3600>;
	};

	oscillator {
		compatible = "fixed-clock";
		#clock-cells = <0x00>;
		phandle = <0x0a>;
		clock-output-names = "xin24m";
		clock-frequency = <0x16e3600>;
	};

	spi@ff110000 {
		compatible = "rockchip,rk3288-spi\0rockchip,rk3066-spi";
		clocks = <0x07 0x41 0x07 0x152>;
		clock-names = "spiclk\0apb_pclk";
		status = "disabled";
		#address-cells = <0x01>;
		interrupts = <0x00 0x2c 0x04>;
		#size-cells = <0x00>;
		dma-names = "tx\0rx";
		reg = <0x00 0xff110000 0x00 0x1000>;
		pinctrl-0 = <0x26 0x27 0x28 0x29>;
		dmas = <0x25 0x0b 0x25 0x0c>;
		pinctrl-names = "default";
	};

	vop@ff940000 {
		power-domains = <0x70 0x09>;
		compatible = "rockchip,rk3288-vop";
		clocks = <0x07 0xc6 0x07 0xbf 0x07 0x1d2>;
		resets = <0x07 0xb0 0x07 0xb1 0x07 0xb2>;
		clock-names = "aclk_vop\0dclk_vop\0hclk_vop";
		status = "okay";
		interrupts = <0x00 0x10 0x04>;
		reg = <0x00 0xff940000 0x00 0x19c 0x00 0xff941000 0x00 0x1000>;
		iommus = <0x75>;
		reset-names = "axi\0ahb\0dclk";

		port {
			#address-cells = <0x01>;
			#size-cells = <0x00>;
			phandle = <0x0b>;

			endpoint@1 {
				remote-endpoint = <0x76>;
				phandle = <0x85>;
				reg = <0x01>;
			};

			endpoint@2 {
				remote-endpoint = <0x77>;
				phandle = <0x79>;
				reg = <0x02>;
			};

			endpoint@3 {
				remote-endpoint = <0x78>;
				phandle = <0x82>;
				reg = <0x03>;
			};
		};
	};

	tsadc@ff280000 {
		rockchip,grf = <0x4a>;
		compatible = "rockchip,rk3288-tsadc";
		clocks = <0x07 0x48 0x07 0x15a>;
		resets = <0x07 0x9f>;
		pinctrl-1 = <0x49>;
		rockchip,hw-tshut-temp = <0x1c138>;
		#thermal-sensor-cells = <0x01>;
		clock-names = "tsadc\0apb_pclk";
		rockchip,hw-tshut-polarity = <0x00>;
		status = "okay";
		interrupts = <0x00 0x25 0x04>;
		phandle = <0x47>;
		pinctrl-2 = <0x48>;
		reg = <0x00 0xff280000 0x00 0x100>;
		pinctrl-0 = <0x48>;
		rockchip,hw-tshut-mode = <0x01>;
		reset-names = "tsadc-apb";
		pinctrl-names = "init\0default\0sleep";
	};

	power-management@ff730000 {
		compatible = "rockchip,rk3288-pmu\0syscon\0simple-mfd";
		phandle = <0x06>;
		reg = <0x00 0xff730000 0x00 0x100>;

		reboot-mode {
			compatible = "syscon-reboot-mode";
			offset = <0x94>;
			mode-update = <0x5242c301>;
			mode-recovery = <0x5242c303>;
			mode-normal = <0x5242c300>;
			mode-loader = <0x5242c301>;
			mode-bootloader = <0x5242c309>;
		};

		power-controller {
			assigned-clock-parents = <0x0a>;
			compatible = "rockchip,rk3288-power-controller";
			#address-cells = <0x01>;
			#size-cells = <0x00>;
			assigned-clocks = <0x07 0x68>;
			phandle = <0x70>;
			#power-domain-cells = <0x01>;

			power-domain@12 {
				clocks = <0x07 0xd0 0x07 0x1dc>;
				pm_qos = <0x6a>;
				reg = <0x0c>;
				#power-domain-cells = <0x00>;
			};

			power-domain@13 {
				clocks = <0x07 0xc0>;
				pm_qos = <0x6b 0x6c>;
				reg = <0x0d>;
				#power-domain-cells = <0x00>;
			};

			power-domain@9 {
				clocks = <0x07 0xca 0x07 0xcd 0x07 0xc8 0x07 0xcc 0x07 0xc5 0x07 0xc6 0x07 0xbe 0x07 0xbf 0x07 0x1d4 0x07 0x1d5 0x07 0x1d6 0x07 0x1d9 0x07 0x1d1 0x07 0x1d2 0x07 0x163 0x07 0x168 0x07 0x167 0x07 0x166 0x07 0x164 0x07 0x165 0x07 0x68 0x07 0x69 0x07 0x6c 0x07 0x6b 0x07 0x6a>;
				pm_qos = <0x5f 0x60 0x61 0x62 0x63 0x64 0x65 0x66 0x67>;
				reg = <0x09>;
				rockchip,pd-always-on;
				#power-domain-cells = <0x00>;
			};

			power-domain@11 {
				clocks = <0x07 0xcf 0x07 0x6f 0x07 0x70>;
				pm_qos = <0x68 0x69>;
				reg = <0x0b>;
				#power-domain-cells = <0x00>;
			};
		};

		bootcount {
			compatible = "syscon-bootcount";
			magic = <0xb001c041>;
			offset = <0xa0>;
		};
	};

	iommu@ff9a0800 {
		power-domains = <0x70 0x0c>;
		compatible = "rockchip,iommu";
		clocks = <0x07 0xd0 0x07 0x1dc>;
		#iommu-cells = <0x00>;
		clock-names = "aclk\0iface";
		status = "disabled";
		interrupts = <0x00 0x0b 0x04>;
		phandle = <0x88>;
		reg = <0x00 0xff9a0800 0x00 0x100>;
	};

	usb@ff520000 {
		compatible = "generic-ohci";
		clocks = <0x07 0x1c2>;
		phy-names = "usb";
		status = "disabled";
		interrupts = <0x00 0x29 0x04>;
		phys = <0x52>;
		reg = <0x00 0xff520000 0x00 0x100>;
	};

	dma-controller@ffb20000 {
		#dma-cells = <0x01>;
		compatible = "arm,pl330\0arm,primecell";
		clocks = <0x07 0xc1>;
		clock-names = "apb_pclk";
		arm,pl330-broken-no-flushp;
		interrupts = <0x00 0x00 0x04 0x00 0x01 0x04>;
		arm,pl330-periph-burst;
		phandle = <0x6d>;
		reg = <0x00 0xffb20000 0x00 0x4000>;
	};

	sound {
		compatible = "inmusic,ada2-audio";
		inmusic,cpu = <0xa9>;
		inmusic,codec = <0xaa>;
	};

	usb-mux {
		compatible = "virtual-mux";
		switch-delay-ms = <0x19>;
		status = "okay";
		post-switch-delay-ms = <0x3e8>;
		default-state = "internal";

		state-internal {

			fragment@1 {
				target = <0xa5>;

				__overlay__ {
					status = "okay";
					pinctrl-0 = <0x34 0xa6>;
					pinctrl-names = "default";
				};
			};

			fragment@2 {
				target = <0xa7>;

				__overlay__ {
					status = "okay";
				};
			};

			fragment@0 {
				target = <0xa4>;

				__overlay__ {
					status = "disabled";
				};
			};
		};

		state-external {

			fragment@1 {
				target = <0xa5>;

				__overlay__ {
					status = "okay";
					pinctrl-0 = <0x34 0xa8>;
					pinctrl-names = "default";
				};
			};

			fragment@2 {
				target = <0xa7>;

				__overlay__ {
					status = "okay";
				};
			};

			fragment@0 {
				target = <0xa4>;

				__overlay__ {
					status = "disabled";
				};
			};
		};
	};

	crypto@ff8a0000 {
		compatible = "rockchip,rk3288-crypto";
		clocks = <0x07 0xc7 0x07 0x1cd 0x07 0x7d 0x07 0xc1>;
		resets = <0x07 0xae>;
		clock-names = "aclk\0hclk\0sclk\0apb_pclk";
		interrupts = <0x00 0x30 0x04>;
		reg = <0x00 0xff8a0000 0x00 0x4000>;
		reset-names = "crypto-rst";
	};

	rga@ff920000 {
		power-domains = <0x70 0x09>;
		compatible = "rockchip,rk3288-rga";
		clocks = <0x07 0xc8 0x07 0x1d6 0x07 0x6a>;
		resets = <0x07 0x69 0x07 0x6c 0x07 0x6d>;
		clock-names = "aclk\0hclk\0sclk";
		interrupts = <0x00 0x12 0x04>;
		reg = <0x00 0xff920000 0x00 0x180>;
		reset-names = "core\0axi\0ahb";
	};

	serial@ff690000 {
		reg-io-width = <0x04>;
		compatible = "rockchip,rk3288-uart\0snps,dw-apb-uart";
		clocks = <0x07 0x4f 0x07 0x157>;
		clock-names = "baudclk\0apb_pclk";
		status = "okay";
		interrupts = <0x00 0x39 0x04>;
		reg = <0x00 0xff690000 0x00 0x100>;
		pinctrl-0 = <0x44>;
		reg-shift = <0x02>;
		pinctrl-names = "default";
	};

	sdio-pwrseq {
		compatible = "mmc-pwrseq-simple";
		clocks = <0x3d>;
		clock-names = "ext_clock";
		reset-gpios = <0x1f 0x1c 0x01>;
		phandle = <0x18>;
		pinctrl-0 = <0x9e>;
		pinctrl-names = "default";
		pre-power-on-delay-ms = <0x0a>;
	};

	regulator-flash {
		compatible = "regulator-fixed";
		phandle = <0x24>;
		startup-delay-us = <0x96>;
		regulator-min-microvolt = <0x1b7740>;
		vin-supply = <0x1d>;
		regulator-max-microvolt = <0x1b7740>;
		regulator-name = "vcc_flash";
	};

	qos@ffaa0000 {
		compatible = "rockchip,rk3288-qos\0syscon";
		phandle = <0x6b>;
		reg = <0x00 0xffaa0000 0x00 0x20>;
	};

	sound@ff8b0000 {
		rockchip,grf = <0x4a>;
		compatible = "rockchip,rk3288-spdif\0rockchip,rk3066-spdif";
		clocks = <0x07 0x54 0x07 0x1d0>;
		#sound-dai-cells = <0x00>;
		clock-names = "mclk\0hclk";
		status = "disabled";
		interrupts = <0x00 0x36 0x04>;
		dma-names = "tx";
		reg = <0x00 0xff8b0000 0x00 0x10000>;
		pinctrl-0 = <0x6e>;
		dmas = <0x6d 0x03>;
		pinctrl-names = "default";
	};

	cpus {
		rockchip,pmu = <0x06>;
		enable-method = "rockchip,rk3066-smp";
		#address-cells = <0x01>;
		#size-cells = <0x00>;

		cpu@501 {
			compatible = "arm,cortex-a12";
			clocks = <0x07 0x06>;
			resets = <0x07 0x01>;
			device_type = "cpu";
			phandle = <0x03>;
			operating-points-v2 = <0x08>;
			dynamic-power-coefficient = <0x172>;
			reg = <0x501>;
			#cooling-cells = <0x02>;
		};

		cpu@502 {
			compatible = "arm,cortex-a12";
			clocks = <0x07 0x06>;
			resets = <0x07 0x02>;
			device_type = "cpu";
			phandle = <0x04>;
			operating-points-v2 = <0x08>;
			dynamic-power-coefficient = <0x172>;
			reg = <0x502>;
			#cooling-cells = <0x02>;
		};

		cpu@500 {
			compatible = "arm,cortex-a12";
			clocks = <0x07 0x06>;
			resets = <0x07 0x00>;
			device_type = "cpu";
			cpu0-supply = <0x09>;
			phandle = <0x02>;
			operating-points-v2 = <0x08>;
			dynamic-power-coefficient = <0x172>;
			reg = <0x500>;
			#cooling-cells = <0x02>;
		};

		cpu@503 {
			compatible = "arm,cortex-a12";
			clocks = <0x07 0x06>;
			resets = <0x07 0x03>;
			device_type = "cpu";
			phandle = <0x05>;
			operating-points-v2 = <0x08>;
			dynamic-power-coefficient = <0x172>;
			reg = <0x503>;
			#cooling-cells = <0x02>;
		};
	};

	qos@ffae0000 {
		compatible = "rockchip,rk3288-qos\0syscon";
		phandle = <0x6a>;
		reg = <0x00 0xffae0000 0x00 0x20>;
	};

	qos@ffad0900 {
		compatible = "rockchip,rk3288-qos\0syscon";
		phandle = <0x67>;
		reg = <0x00 0xffad0900 0x00 0x20>;
	};

	dwmmc@ff0e0000 {
		compatible = "rockchip,rk3288-dw-mshc";
		clocks = <0x07 0x1ca 0x07 0x46 0x07 0x74 0x07 0x78>;
		resets = <0x07 0x82>;
		clock-names = "biu\0ciu\0ciu-drive\0ciu-sample";
		fifo-depth = <0x100>;
		status = "disabled";
		interrupts = <0x00 0x22 0x04>;
		reg = <0x00 0xff0e0000 0x00 0x4000>;
		reset-names = "reset";
		max-frequency = <0x8f0d180>;
	};

	i2c@ff650000 {
		compatible = "rockchip,rk3288-i2c";
		clocks = <0x07 0x14c>;
		clock-names = "i2c";
		status = "okay";
		#address-cells = <0x01>;
		interrupts = <0x00 0x3c 0x04>;
		#size-cells = <0x00>;
		reg = <0x00 0xff650000 0x00 0x1000>;
		pinctrl-0 = <0x55>;
		pinctrl-names = "default";

		syr827@40 {
			regulator-enable-ramp-delay = <0x12c>;
			compatible = "silergy,syr827";
			regulator-boot-on;
			phandle = <0x09>;
			regulator-min-microvolt = <0xcf850>;
			vin-supply = <0x56>;
			reg = <0x40>;
			regulator-max-microvolt = <0x16e360>;
			regulator-always-on;
			regulator-name = "vdd_cpu";
			regulator-initial-mode = <0x01>;
			fcs,suspend-voltage-selector = <0x01>;
			regulator-ramp-delay = <0x1f40>;
		};

		syr828@41 {
			regulator-enable-ramp-delay = <0x12c>;
			compatible = "silergy,syr828";
			phandle = <0x8a>;
			regulator-min-microvolt = <0xcf850>;
			vin-supply = <0x56>;
			reg = <0x41>;
			regulator-max-microvolt = <0x149970>;
			regulator-always-on;
			regulator-name = "vdd_gpu";
			regulator-initial-mode = <0x01>;
			fcs,suspend-voltage-selector = <0x01>;
			regulator-ramp-delay = <0x1f40>;
		};

		act8846@5a {
			compatible = "active-semi,act8846";
			inl1-supply = <0x1d>;
			vp4-supply = <0x56>;
			vp3-supply = <0x56>;
			vp2-supply = <0x56>;
			system-power-controller;
			vp1-supply = <0x56>;
			reg = <0x5a>;
			inl3-supply = <0x57>;
			inl2-supply = <0x56>;

			regulators {

				REG3 {
					regulator-min-microvolt = <0xe7ef0>;
					regulator-max-microvolt = <0x155cc0>;
					regulator-always-on;
					regulator-name = "VDD_LOG";
				};

				REG1 {
					regulator-min-microvolt = <0x124f80>;
					regulator-max-microvolt = <0x16e360>;
					regulator-always-on;
					regulator-name = "VCC_DDR";
				};

				REG12 {
					regulator-min-microvolt = <0x1b7740>;
					regulator-max-microvolt = <0x1b7740>;
					regulator-always-on;
					regulator-name = "VCC18_LCD";
				};

				REG10 {
					regulator-min-microvolt = <0xf4240>;
					regulator-max-microvolt = <0xf4240>;
					regulator-always-on;
					regulator-name = "VDD_10";
				};

				REG8 {
					regulator-min-microvolt = <0x325aa0>;
					regulator-max-microvolt = <0x325aa0>;
					regulator-always-on;
					regulator-name = "VCCA_TP";
				};

				REG6 {
					regulator-min-microvolt = <0xf4240>;
					regulator-max-microvolt = <0xf4240>;
					regulator-always-on;
					regulator-name = "VDD10_LCD";
				};

				REG4 {
					phandle = <0x57>;
					regulator-min-microvolt = <0x1e8480>;
					regulator-max-microvolt = <0x1e8480>;
					regulator-always-on;
					regulator-name = "VCC_20";
				};

				REG2 {
					phandle = <0x1d>;
					regulator-min-microvolt = <0x325aa0>;
					regulator-max-microvolt = <0x325aa0>;
					regulator-always-on;
					regulator-name = "VCC_IO";
				};

				REG11 {
					phandle = <0x1e>;
					regulator-min-microvolt = <0x1b7740>;
					regulator-max-microvolt = <0x1b7740>;
					regulator-always-on;
					regulator-name = "VCC_18";
				};

				REG9 {
					phandle = <0x4d>;
					regulator-min-microvolt = <0x325aa0>;
					regulator-max-microvolt = <0x325aa0>;
					regulator-always-on;
					regulator-name = "VCCIO_PMU";
				};

				REG7 {
					regulator-min-microvolt = <0x325aa0>;
					regulator-max-microvolt = <0x325aa0>;
					regulator-always-on;
					regulator-name = "VCCA_CODEC";
				};

				REG5 {
					phandle = <0x17>;
					regulator-min-microvolt = <0x1b7740>;
					regulator-max-microvolt = <0x325aa0>;
					regulator-always-on;
					regulator-name = "VCCIO_SD";
				};
			};
		};

		hym8563@51 {
			compatible = "haoyu,hym8563";
			interrupt-parent = <0x58>;
			interrupts = <0x04 0x02>;
			haoyu,clock-is-critical;
			#clock-cells = <0x00>;
			phandle = <0x3d>;
			reg = <0x51>;
			clock-output-names = "xin32k";
			clock-frequency = <0x8000>;
			pinctrl-0 = <0x59>;
			pinctrl-names = "default";
		};
	};

	i2c@ff160000 {
		compatible = "rockchip,rk3288-i2c";
		clocks = <0x07 0x150>;
		resets = <0x07 0x2e>;
		clock-names = "i2c";
		status = "okay";
		#address-cells = <0x01>;
		interrupts = <0x00 0x40 0x04>;
		#size-cells = <0x00>;
		reg = <0x00 0xff160000 0x00 0x1000>;
		pinctrl-0 = <0x36>;
		reset-names = "i2c";
		pinctrl-names = "default";

		st1727@55 {
			gpios = <0x33 0x05 0x01>;
			compatible = "sitronix,st1727";
			status = "disabled";
			interrupt-parent = <0x33>;
			interrupts = <0x06 0x02>;
			reg = <0x55>;
			pinctrl-0 = <0x37 0x38>;
			pinctrl-names = "default";
		};

		ili2117@26 {
			compatible = "ilitek,ili2117";
			irq-gpios = <0x33 0x06 0x00>;
			reg-names = "default\0upgrade";
			status = "disabled";
			interrupt-parent = <0x33>;
			interrupts = <0x06 0x02>;
			reset-gpios = <0x33 0x05 0x01>;
			reg = <0x26 0x62>;
			pinctrl-0 = <0x37 0x38>;
			pinctrl-names = "default";
		};

		ili2116@41 {
			compatible = "ilitek,ili2116";
			irq-gpios = <0x33 0x06 0x00>;
			status = "okay";
			interrupt-parent = <0x33>;
			interrupts = <0x06 0x02>;
			reset-gpios = <0x33 0x05 0x01>;
			reg = <0x41>;
			pinctrl-0 = <0x37 0x38>;
			pinctrl-names = "default";
		};
	};

	vcc-mipi {
		compatible = "regulator-fixed";
		regulator-boot-on;
		gpio = <0x33 0x04 0x01>;
		phandle = <0x7c>;
		startup-delay-us = <0x2710>;
		regulator-min-microvolt = <0x325aa0>;
		vin-supply = <0x56>;
		regulator-max-microvolt = <0x325aa0>;
		pinctrl-0 = <0x9f>;
		regulator-name = "vcc_mipi";
		pinctrl-names = "default";
	};

	qos@ffaf0080 {
		compatible = "rockchip,rk3288-qos\0syscon";
		phandle = <0x69>;
		reg = <0x00 0xffaf0080 0x00 0x20>;
	};

	spi@ff120000 {
		compatible = "rockchip,rk3288-spi\0rockchip,rk3066-spi";
		clocks = <0x07 0x42 0x07 0x153>;
		clock-names = "spiclk\0apb_pclk";
		status = "disabled";
		#address-cells = <0x01>;
		interrupts = <0x00 0x2d 0x04>;
		#size-cells = <0x00>;
		dma-names = "tx\0rx";
		reg = <0x00 0xff120000 0x00 0x1000>;
		pinctrl-0 = <0x2a 0x2b 0x2c 0x2d>;
		dmas = <0x25 0x0d 0x25 0x0e>;
		pinctrl-names = "default";
	};

	sram@ff720000 {
		compatible = "rockchip,rk3288-pmu-sram\0mmio-sram";
		reg = <0x00 0xff720000 0x00 0x1000>;
	};

	pinctrl {
		rockchip,pmu = <0x06>;
		rockchip,grf = <0x4a>;
		compatible = "rockchip,rk3288-pinctrl";
		ranges;
		#address-cells = <0x02>;
		#size-cells = <0x02>;
		pinctrl-0 = <0x8b>;
		pinctrl-names = "default";

		i2c3 {

			i2c3-xfer {
				phandle = <0x35>;
				rockchip,pins = <0x02 0x10 0x01 0x8c 0x02 0x11 0x01 0x8c>;
			};
		};

		sdio1 {

			sdio1-bus1 {
				rockchip,pins = <0x03 0x18 0x04 0x8e>;
			};

			sdio1-bus4 {
				rockchip,pins = <0x03 0x18 0x04 0x8e 0x03 0x19 0x04 0x8e 0x03 0x1a 0x04 0x8e 0x03 0x1b 0x04 0x8e>;
			};

			sdio1-pwr {
				rockchip,pins = <0x04 0x09 0x04 0x8e>;
			};

			sdio1-int {
				rockchip,pins = <0x03 0x1f 0x04 0x8e>;
			};

			sdio1-wp {
				rockchip,pins = <0x03 0x1d 0x04 0x8e>;
			};

			sdio1-cmd {
				rockchip,pins = <0x04 0x06 0x04 0x8e>;
			};

			sdio1-bkpwr {
				rockchip,pins = <0x03 0x1e 0x04 0x8e>;
			};

			sdio1-clk {
				rockchip,pins = <0x04 0x07 0x04 0x8c>;
			};

			sdio1-cd {
				rockchip,pins = <0x03 0x1c 0x04 0x8e>;
			};
		};

		spi2 {

			spi2-cs1 {
				rockchip,pins = <0x08 0x03 0x01 0x8e>;
			};

			spi2-clk {
				phandle = <0x2e>;
				rockchip,pins = <0x08 0x06 0x01 0x8e>;
			};

			spi2-tx {
				phandle = <0x2f>;
				rockchip,pins = <0x08 0x09 0x01 0x8e>;
			};

			spi2-rx {
				phandle = <0x30>;
				rockchip,pins = <0x08 0x08 0x01 0x8e>;
			};

			spi2-cs0 {
				phandle = <0x31>;
				rockchip,pins = <0x08 0x07 0x01 0x8e>;
			};
		};

		i2c1 {

			i2c1-xfer {
				phandle = <0x32>;
				rockchip,pins = <0x08 0x04 0x01 0x8c 0x08 0x05 0x01 0x8c>;
			};
		};

		gpio@ff7b0000 {
			compatible = "rockchip,gpio-bank";
			clocks = <0x07 0x144>;
			gpio-line-names = "FLASH1_RDY\0FLASH1_WP\0FLASH1_RDN\0FLASH1_ALE\0MAC_TXEN\0FLASH1_WRN\0FLASH1_CSn0\0FLASH1_CSn1\0FLASH1_DQS\0MAC_TXCLK\0\0\0\0\0\0\0UART0_RXD\0UART0_TXD\0UART0_CTS\0UART0_RTS\0WIFI_D0\0WIFI_D1\0WIFI_D2\0WIFI_D3\0WIFI_CMD\0WIFI_CLK\0BT_WAKE\0BT_REG_ON\0WIFI_REG_ON\0BT_RST\0WIFI_HOST_WAKE\0BT_HOST_WAKE";
			gpio-controller;
			#interrupt-cells = <0x02>;
			interrupts = <0x00 0x55 0x04>;
			phandle = <0x1f>;
			reg = <0x00 0xff7b0000 0x00 0x100>;
			#gpio-cells = <0x02>;
			interrupt-controller;
		};

		gmac {

			phy-rst {
				phandle = <0x50>;
				rockchip,pins = <0x04 0x08 0x00 0x94>;
			};

			rmii-pins {
				rockchip,pins = <0x03 0x1e 0x03 0x8c 0x03 0x1f 0x03 0x8c 0x03 0x1c 0x03 0x8c 0x03 0x1d 0x03 0x8c 0x04 0x00 0x03 0x8c 0x04 0x05 0x03 0x8c 0x04 0x04 0x03 0x8c 0x04 0x01 0x03 0x8c 0x04 0x02 0x03 0x8c 0x04 0x03 0x03 0x8c>;
			};

			phy-int {
				phandle = <0x4f>;
				rockchip,pins = <0x03 0x0f 0x00 0x8e>;
			};

			rgmii-pins {
				phandle = <0x4e>;
				rockchip,pins = <0x03 0x1e 0x03 0x8c 0x03 0x1f 0x03 0x8c 0x03 0x1a 0x03 0x8c 0x03 0x1b 0x03 0x8c 0x03 0x1c 0x03 0x92 0x03 0x1d 0x03 0x92 0x03 0x18 0x03 0x92 0x03 0x19 0x03 0x92 0x04 0x00 0x03 0x8c 0x04 0x05 0x03 0x8c 0x04 0x06 0x03 0x8c 0x04 0x09 0x03 0x92 0x04 0x04 0x03 0x92 0x04 0x01 0x03 0x8c 0x04 0x03 0x03 0x8c>;
			};
		};

		pcfg-output-4ma-slow {
			bias-disable;
			slew-rate = <0x00>;
			drive-strength = <0x04>;
			phandle = <0x90>;
		};

		pcfg-output-4ma-fast {
			bias-disable;
			slew-rate = <0x01>;
			drive-strength = <0x04>;
			phandle = <0x91>;
		};

		touch {

			touch-int {
				phandle = <0x37>;
				rockchip,pins = <0x07 0x06 0x00 0x8e>;
			};

			touch-rst {
				phandle = <0x38>;
				rockchip,pins = <0x07 0x05 0x00 0x8c>;
			};
		};

		pcfg-pull-none-2ma {
			bias-disable;
			drive-strength = <0x02>;
			phandle = <0x95>;
		};

		gpio@ff7f0000 {
			compatible = "rockchip,gpio-bank";
			clocks = <0x07 0x148>;
			gpio-line-names = "nLVDS_ON\0USB_MUX_CTRL\0PMU_VSEL\0\0I2C1_SDA\0I2C1_SCL\0\0\0\0";
			gpio-controller;
			#interrupt-cells = <0x02>;
			interrupts = <0x00 0x59 0x04>;
			reg = <0x00 0xff7f0000 0x00 0x100>;
			#gpio-cells = <0x02>;
			interrupt-controller;
		};

		spi0 {

			spi0-clk {
				phandle = <0x26>;
				rockchip,pins = <0x05 0x0c 0x01 0x8e>;
			};

			spi0-tx {
				phandle = <0x27>;
				rockchip,pins = <0x05 0x0e 0x01 0x8e>;
			};

			spi0-cs0 {
				phandle = <0x29>;
				rockchip,pins = <0x05 0x0d 0x01 0x8e>;
			};

			spi0-rx {
				phandle = <0x28>;
				rockchip,pins = <0x05 0x0f 0x01 0x8e>;
			};

			spi0-cs1 {
				rockchip,pins = <0x05 0x10 0x01 0x8e>;
			};
		};

		gpio@ff780000 {
			compatible = "rockchip,gpio-bank";
			clocks = <0x07 0x141>;
			gpio-controller;
			#interrupt-cells = <0x02>;
			interrupts = <0x00 0x52 0x04>;
			reg = <0x00 0xff780000 0x00 0x100>;
			#gpio-cells = <0x02>;
			interrupt-controller;
		};

		pcfg-pull-none-12ma-slow {
			bias-disable;
			slew-rate = <0x00>;
			drive-strength = <0x0c>;
		};

		pcfg-pull-down {
			phandle = <0x8f>;
			bias-pull-down;
		};

		az01 {

			az01-pcb-rev {
				phandle = <0x8b>;
				rockchip,pins = <0x02 0x08 0x00 0x8e 0x02 0x0b 0x00 0x8e 0x02 0x0d 0x00 0x8e 0x02 0x0e 0x00 0x8e>;
			};
		};

		bluetooth {

			bt-wake {
				phandle = <0x3f>;
				rockchip,pins = <0x04 0x1a 0x00 0x8c>;
			};

			bt-host-wake {
				phandle = <0x40>;
				rockchip,pins = <0x04 0x1f 0x00 0x8e>;
			};

			bt-reg-on {
				phandle = <0x3e>;
				rockchip,pins = <0x04 0x1d 0x00 0x8c>;
			};
		};

		pcfg-pull-none-12ma {
			bias-disable;
			drive-strength = <0x0c>;
			phandle = <0x92>;
		};

		pwm3 {

			pwm3-pin {
				phandle = <0x5e>;
				rockchip,pins = <0x07 0x17 0x03 0x8c>;
			};
		};

		uart4 {

			uart4-xfer {
				phandle = <0x46>;
				rockchip,pins = <0x05 0x0f 0x03 0x8e 0x05 0x0e 0x03 0x8c>;
			};

			uart4-cts {
				rockchip,pins = <0x05 0x0c 0x03 0x8e>;
			};

			uart4-rts {
				rockchip,pins = <0x05 0x0d 0x03 0x8c>;
			};
		};

		usb_otg {

			otg-vbus-drv {
				phandle = <0xa3>;
				rockchip,pins = <0x00 0x0c 0x00 0x8c>;
			};
		};

		reboot {

			pwr-off-delay {
				phandle = <0x99>;
				rockchip,pins = <0x00 0x09 0x00 0x8c>;
			};
		};

		gpio@ff7c0000 {
			compatible = "rockchip,gpio-bank";
			clocks = <0x07 0x145>;
			gpio-line-names = "\0\0\0\0\0\0\0\0UART1_SIN\0UART1_SOUT\0UART1_CTSn\0UART1_RTSn\0SPI0_CLK\0SPI0_CSn0\0SPI0_TXD\0SPI0_RXD\0SPI0_CSn1\0\0\0";
			gpio-controller;
			#interrupt-cells = <0x02>;
			interrupts = <0x00 0x56 0x04>;
			reg = <0x00 0xff7c0000 0x00 0x100>;
			#gpio-cells = <0x02>;
			interrupt-controller;
		};

		lcdc {

			lcdc-ctl {
				phandle = <0x80>;
				rockchip,pins = <0x01 0x18 0x01 0x8c 0x01 0x19 0x01 0x8c 0x01 0x1a 0x01 0x8c 0x01 0x1b 0x01 0x8c>;
			};
		};

		leds {

			led2 {
				phandle = <0x9b>;
				rockchip,pins = <0x00 0x0b 0x00 0x8c>;
			};

			led-1 {
				rockchip,pins = <0x07 0x0f 0x00 0x8c>;
			};

			led-2 {
				rockchip,pins = <0x00 0x0b 0x00 0x8c>;
			};

			led1 {
				phandle = <0x9a>;
				rockchip,pins = <0x07 0x0f 0x00 0x8c>;
			};
		};

		gpio@ff750000 {
			compatible = "rockchip,gpio-bank";
			clocks = <0x07 0x140>;
			gpio-line-names = "PMU_SLEEP\0DDRIO_PWROFF\0DDRIO_RETEN\0EFUSE_PWR\0PMIC_INT\0PWR_KEY\0\0\0\0PWR_OFF_DELAY\0PWR_HOLD\0LED_STATE2\0\0SATA_PWR_EN\0\0I2C0_SDA_PMU\0I2C0_SCL_PMU\0\0USB_INT";
			gpio-controller;
			#interrupt-cells = <0x02>;
			interrupts = <0x00 0x51 0x04>;
			phandle = <0x58>;
			reg = <0x00 0xff750000 0x00 0x100>;
			#gpio-cells = <0x02>;
			interrupt-controller;
		};

		edp {

			edp-hpd {
				rockchip,pins = <0x07 0x0b 0x02 0x8f>;
			};
		};

		pwm1 {

			pwm1-pin {
				phandle = <0x5c>;
				rockchip,pins = <0x07 0x01 0x01 0x8c>;
			};
		};

		uart2 {

			uart2-xfer {
				phandle = <0x44>;
				rockchip,pins = <0x07 0x16 0x01 0x8e 0x07 0x17 0x01 0x8c>;
			};
		};

		sound-codec {

			codec-clksel {
				rockchip,pins = <0x06 0x0b 0x00 0x8c 0x06 0x08 0x00 0x8c>;
			};

			mute {
				phandle = <0xab>;
				rockchip,pins = <0x02 0x02 0x00 0x8c>;
			};

			an-power-en {
				phandle = <0xad>;
				rockchip,pins = <0x02 0x01 0x00 0x8c>;
			};

			codec-reset {
				phandle = <0xac>;
				rockchip,pins = <0x02 0x00 0x00 0x8c>;
			};
		};

		sata {

			sata-pwr {
				phandle = <0xa0>;
				rockchip,pins = <0x00 0x0d 0x00 0x8c>;
			};

			sata-reset {
				rockchip,pins = <0x07 0x15 0x00 0x8c>;
			};
		};

		gpio@ff790000 {
			compatible = "rockchip,gpio-bank";
			clocks = <0x07 0x142>;
			gpio-line-names = "nCODEC_RESET\0nAN_POWER_EN\0MUTE\0GPIO2_A3\0GPIO2_A4\0\0\0MIPI_RESET\0\0\0\0\0\0\0\0\0I2C3_SCL_CAM\0I2C3_SDA_CAM";
			gpio-controller;
			#interrupt-cells = <0x02>;
			interrupts = <0x00 0x53 0x04>;
			phandle = <0x7d>;
			reg = <0x00 0xff790000 0x00 0x100>;
			#gpio-cells = <0x02>;
			interrupt-controller;
		};

		pcfg-pull-up {
			phandle = <0x8e>;
			bias-pull-up;
		};

		pcfg-output-high {
			bias-disable;
			phandle = <0x94>;
			output-high;
		};

		pcfg-pull-up-12ma {
			drive-strength = <0x0c>;
			phandle = <0x93>;
			bias-pull-up;
		};

		i2c4 {

			i2c4-xfer {
				phandle = <0x36>;
				rockchip,pins = <0x07 0x11 0x01 0x8c 0x07 0x12 0x01 0x8c>;
			};
		};

		emmc {

			emmc-cmd {
				phandle = <0x22>;
				rockchip,pins = <0x03 0x10 0x02 0x8e>;
			};

			emmc-clk {
				phandle = <0x21>;
				rockchip,pins = <0x03 0x12 0x02 0x8c>;
			};

			emmc-bus1 {
				rockchip,pins = <0x03 0x00 0x02 0x8e>;
			};

			emmc-reset {
				phandle = <0x96>;
				rockchip,pins = <0x03 0x09 0x00 0x8c>;
			};

			emmc-bus8 {
				phandle = <0x23>;
				rockchip,pins = <0x03 0x00 0x02 0x8e 0x03 0x01 0x02 0x8e 0x03 0x02 0x02 0x8e 0x03 0x03 0x02 0x8e 0x03 0x04 0x02 0x8e 0x03 0x05 0x02 0x8e 0x03 0x06 0x02 0x8e 0x03 0x07 0x02 0x8e>;
			};

			emmc-bus4 {
				rockchip,pins = <0x03 0x00 0x02 0x8e 0x03 0x01 0x02 0x8e 0x03 0x02 0x02 0x8e 0x03 0x03 0x02 0x8e>;
			};

			emmc-pwr {
				rockchip,pins = <0x03 0x09 0x02 0x8e>;
			};
		};

		tsadc {

			otp-pin {
				phandle = <0x48>;
				rockchip,pins = <0x00 0x0a 0x00 0x94>;
			};

			otp-out {
				phandle = <0x49>;
				rockchip,pins = <0x00 0x0a 0x01 0x8c>;
			};
		};

		uart0 {

			uart0-cts {
				phandle = <0x3b>;
				rockchip,pins = <0x04 0x12 0x01 0x8e>;
			};

			uart0-xfer {
				phandle = <0x3a>;
				rockchip,pins = <0x04 0x10 0x01 0x8e 0x04 0x11 0x01 0x8c>;
			};

			uart0-rts {
				phandle = <0x3c>;
				rockchip,pins = <0x04 0x13 0x01 0x8c>;
			};
		};

		mipi_panel {

			lcd-cs {
				phandle = <0x9f>;
				rockchip,pins = <0x07 0x04 0x00 0x8c>;
			};

			mipi-reset {
				phandle = <0x7b>;
				rockchip,pins = <0x02 0x07 0x00 0x8c>;
			};
		};

		i2c2 {

			i2c2-xfer {
				phandle = <0x5a>;
				rockchip,pins = <0x06 0x09 0x01 0x8c 0x06 0x0a 0x01 0x8c>;
			};
		};

		spdif {

			spdif-tx {
				phandle = <0x6e>;
				rockchip,pins = <0x06 0x0b 0x01 0x8c>;
			};
		};

		pcfg-pull-none {
			bias-disable;
			phandle = <0x8c>;
		};

		pmic {

			pmic-int {
				phandle = <0x59>;
				rockchip,pins = <0x00 0x04 0x00 0x8e>;
			};
		};

		sdio0 {

			sdio0-bus1 {
				rockchip,pins = <0x04 0x14 0x01 0x8e>;
			};

			sdio0-pwr {
				rockchip,pins = <0x04 0x1c 0x01 0x8e>;
			};

			sdio0-int {
				phandle = <0x1c>;
				rockchip,pins = <0x04 0x1e 0x01 0x8e>;
			};

			sdio0-cd {
				rockchip,pins = <0x04 0x1a 0x01 0x8e>;
			};

			sdio0-cmd {
				phandle = <0x1a>;
				rockchip,pins = <0x04 0x18 0x01 0x8e>;
			};

			sdio0-bkpwr {
				rockchip,pins = <0x04 0x1d 0x01 0x8e>;
			};

			sdio0-bus4 {
				phandle = <0x19>;
				rockchip,pins = <0x04 0x14 0x01 0x8e 0x04 0x15 0x01 0x8e 0x04 0x16 0x01 0x8e 0x04 0x17 0x01 0x8e>;
			};

			sdio0-clk {
				phandle = <0x1b>;
				rockchip,pins = <0x04 0x19 0x01 0x8c>;
			};

			sdio0-wp {
				rockchip,pins = <0x04 0x1b 0x01 0x8e>;
			};
		};

		spi1 {

			spi1-tx {
				phandle = <0x2b>;
				rockchip,pins = <0x07 0x0f 0x02 0x8e>;
			};

			spi1-rx {
				phandle = <0x2c>;
				rockchip,pins = <0x07 0x0e 0x02 0x8e>;
			};

			spi1-clk {
				phandle = <0x2a>;
				rockchip,pins = <0x07 0x0c 0x02 0x8e>;
			};

			spi1-cs0 {
				phandle = <0x2d>;
				rockchip,pins = <0x07 0x0d 0x02 0x8e>;
			};
		};

		gpio@ff7d0000 {
			compatible = "rockchip,gpio-bank";
			clocks = <0x07 0x146>;
			gpio-line-names = "I2S0_SCLK\0I2S0_LRCK_RX\0I2S0_LRCK_TX\0I2S0_SDI\0I2S0_SDO0\0I2S0_SDO1\0I2S0_SDO2\0I2S0_SDO3\0I2S0_CLK\0I2C2_SDA_AUDIO\0I2C2_SCL_AUDIO\0SPDIF_TX\0\0\0\0\0SDMMC_D0\0SDMMC_D1\0SDMMC_D2\0SDMMC_D3\0SDMMC_CLK\0SDMMC_CMD\0SDMMC_DET_EXT";
			gpio-controller;
			#interrupt-cells = <0x02>;
			interrupts = <0x00 0x57 0x04>;
			reg = <0x00 0xff7d0000 0x00 0x100>;
			#gpio-cells = <0x02>;
			interrupt-controller;
		};

		i2s0 {

			i2s0-bus {
				phandle = <0x6f>;
				rockchip,pins = <0x06 0x00 0x01 0x90 0x06 0x01 0x01 0x90 0x06 0x02 0x01 0x90 0x06 0x03 0x01 0x90 0x06 0x04 0x01 0x90 0x06 0x05 0x01 0x90 0x06 0x06 0x01 0x90 0x06 0x07 0x01 0x90 0x06 0x08 0x01 0x91>;
			};
		};

		i2c0 {

			i2c0-xfer {
				phandle = <0x55>;
				rockchip,pins = <0x00 0x0f 0x01 0x8c 0x00 0x10 0x01 0x8c>;
			};
		};

		sdio {

			wifi-enable {
				phandle = <0x9e>;
				rockchip,pins = <0x04 0x1c 0x00 0x8c>;
			};
		};

		sdmmc {

			sdmmc-cd {
				rockchip,pins = <0x06 0x16 0x01 0x93>;
			};

			sdmmc-bus4 {
				phandle = <0x10>;
				rockchip,pins = <0x06 0x10 0x01 0x93 0x06 0x11 0x01 0x93 0x06 0x12 0x01 0x93 0x06 0x13 0x01 0x93>;
			};

			sdmmc-pwr {
				phandle = <0xa1>;
				rockchip,pins = <0x07 0x0b 0x00 0x8c>;
			};

			sdmmc-wp-gpio {
				phandle = <0x13>;
				rockchip,pins = <0x06 0x16 0x00 0x8e>;
			};

			sdmmc-ext-cd-gpio {
				phandle = <0x11>;
				rockchip,pins = <0x04 0x1b 0x00 0x8e>;
			};

			sdmmc-sel-int {
				phandle = <0x14>;
				rockchip,pins = <0x02 0x06 0x00 0x8d>;
			};

			sdmmc-cmd {
				phandle = <0x0f>;
				rockchip,pins = <0x06 0x15 0x01 0x93>;
			};

			sdmmc-clk {
				phandle = <0x0e>;
				rockchip,pins = <0x06 0x14 0x01 0x92>;
			};

			sdmmc-gpios {
				phandle = <0x15>;
				rockchip,pins = <0x06 0x10 0x00 0x8d 0x06 0x11 0x00 0x8d 0x06 0x12 0x00 0x8d 0x06 0x13 0x00 0x8d 0x06 0x14 0x00 0x8d 0x06 0x15 0x00 0x8d>;
			};

			sdmmc-sel-ext {
				rockchip,pins = <0x02 0x06 0x00 0x94>;
			};

			sdmmc-bus1 {
				rockchip,pins = <0x06 0x10 0x01 0x93>;
			};

			sdmmc-int-cd-gpio {
				phandle = <0x12>;
				rockchip,pins = <0x02 0x05 0x00 0x8e>;
			};
		};

		vcc_lcd {

			lcd-en {
				rockchip,pins = <0x07 0x03 0x00 0x8c>;
			};
		};

		pcfg-output-low {
			output-low;
			bias-disable;
			phandle = <0x8d>;
		};

		suspend {

			ddr1-retention {
				rockchip,pins = <0x00 0x03 0x01 0x8e>;
			};

			global-pwroff {
				rockchip,pins = <0x00 0x00 0x01 0x8c>;
			};

			ddrio-pwroff {
				rockchip,pins = <0x00 0x01 0x01 0x8c>;
			};

			ddr0-retention {
				rockchip,pins = <0x00 0x02 0x01 0x8e>;
			};
		};

		gpio@ff7a0000 {
			compatible = "rockchip,gpio-bank";
			clocks = <0x07 0x143>;
			gpio-line-names = "FLASH0_D0\0FLASH0_D1\0FLASH0_D2\0FLASH0_D3\0FLASH0_D4\0FLASH0_D5\0FLASH0_D6\0FLASH0_D7\0\0EMMC_PWREN\0\0\0\0\0PHY_PMEB\0PHY_INT\0EMMC_CMD\0EMMC_RST\0EMMC_CLKO\0FLASH0_VOLTAGE_SEL\0\0\0\0\0MAC_TXD2\0MAC_TXD3\0FLASH1_D2\0FLASH1_D3\0MAC_TXD0\0MAC_TXD1\0FLASH1_D6\0FLASH1_D7";
			gpio-controller;
			#interrupt-cells = <0x02>;
			interrupts = <0x00 0x54 0x04>;
			phandle = <0x51>;
			reg = <0x00 0xff7a0000 0x00 0x100>;
			#gpio-cells = <0x02>;
			interrupt-controller;
		};

		pwm2 {

			pwm2-pin {
				phandle = <0x5d>;
				rockchip,pins = <0x07 0x16 0x03 0x8c>;
			};
		};

		uart3 {

			uart3-xfer {
				phandle = <0x45>;
				rockchip,pins = <0x07 0x07 0x01 0x8e 0x07 0x08 0x01 0x8c>;
			};

			uart3-cts {
				rockchip,pins = <0x07 0x09 0x01 0x8e>;
			};

			uart3-rts {
				rockchip,pins = <0x07 0x0a 0x01 0x8c>;
			};
		};

		gpio@ff7e0000 {
			compatible = "rockchip,gpio-bank";
			clocks = <0x07 0x147>;
			gpio-line-names = "PWM_LVDS\0PWM_MIPI\0nUSB_HUB_RESET\0\0nMIPI_ON\0TOUCH_RST\0TOUCH_INT\0UART3_RXD\0UART3_TXD\0\0\0SDMMC_PWR\0POWER_OUT\0\0\0LED_STATE1\0HDMI_CEC\0I2C4_SDA_TP\0I2C4_SCL_TP\0I2C5_SDA_HDMI\0I2C5_SCL_HDMI\0SATA_RST\0UART2_RXD\0UART2_TXD";
			gpio-controller;
			#interrupt-cells = <0x02>;
			interrupts = <0x00 0x58 0x04>;
			phandle = <0x33>;
			reg = <0x00 0xff7e0000 0x00 0x100>;
			#gpio-cells = <0x02>;
			interrupt-controller;

			sata-reset-asserted {
				gpios = <0x15 0x00>;
				gpio-hog;
				status = "disabled";
				phandle = <0xa4>;
				line-name = "sata_reset";
				output-high;
			};

			sata-reset-deasserted {
				gpios = <0x15 0x00>;
				output-low;
				gpio-hog;
				status = "okay";
				phandle = <0xa7>;
				line-name = "sata_reset";
			};
		};

		hdmi {

			hdmi-ddc {
				rockchip,pins = <0x07 0x13 0x02 0x8c 0x07 0x14 0x02 0x8c>;
			};

			hdmi-ddc-unwedge {
				rockchip,pins = <0x07 0x13 0x00 0x8d 0x07 0x14 0x02 0x8c>;
			};

			hdmi-cec-c0 {
				rockchip,pins = <0x07 0x10 0x02 0x8c>;
			};

			hdmi-cec-c7 {
				rockchip,pins = <0x07 0x17 0x04 0x8c>;
			};
		};

		i2c5 {

			i2c5-xfer {
				phandle = <0x39>;
				rockchip,pins = <0x07 0x13 0x01 0x8c 0x07 0x14 0x01 0x8c>;
			};
		};

		pwm0 {

			pwm0-pin {
				phandle = <0x5b>;
				rockchip,pins = <0x07 0x00 0x01 0x8c>;
			};
		};

		uart1 {

			uart1-xfer {
				phandle = <0x41>;
				rockchip,pins = <0x05 0x08 0x01 0x8e 0x05 0x09 0x01 0x8c>;
			};

			uart1-cts {
				phandle = <0x42>;
				rockchip,pins = <0x05 0x0a 0x01 0x8e>;
			};

			uart1-rts {
				phandle = <0x43>;
				rockchip,pins = <0x05 0x0b 0x01 0x8c>;
			};
		};

		usb_host {

			host-vbus-drv {
				phandle = <0xa2>;
				rockchip,pins = <0x00 0x0e 0x00 0x8c>;
			};
		};

		buttons {

			pwr-key-l {
				phandle = <0x98>;
				rockchip,pins = <0x00 0x05 0x00 0x8e>;
			};
		};

		usb-hub {

			usb-sel-int {
				phandle = <0xa6>;
				rockchip,pins = <0x08 0x01 0x00 0x94>;
			};

			usb-sel-ext {
				phandle = <0xa8>;
				rockchip,pins = <0x08 0x01 0x00 0x8d>;
			};

			usb-reset-pin {
				phandle = <0x34>;
				rockchip,pins = <0x07 0x02 0x00 0x95>;
			};

			usb-mux-sel {
				rockchip,pins = <0x08 0x01 0x00 0x8c>;
			};
		};
	};

	pwm@ff680030 {
		compatible = "rockchip,rk3288-pwm";
		clocks = <0x07 0x15f>;
		status = "disabled";
		reg = <0x00 0xff680030 0x00 0x10>;
		pinctrl-0 = <0x5e>;
		#pwm-cells = <0x03>;
		pinctrl-names = "default";
	};

	qos@ffad0880 {
		compatible = "rockchip,rk3288-qos\0syscon";
		phandle = <0x66>;
		reg = <0x00 0xffad0880 0x00 0x20>;
	};

	iommu@ff900800 {
		compatible = "rockchip,iommu";
		clocks = <0x07 0xca 0x07 0x1d4>;
		#iommu-cells = <0x00>;
		clock-names = "aclk\0iface";
		status = "disabled";
		interrupts = <0x00 0x11 0x04>;
		reg = <0x00 0xff900800 0x00 0x40>;
	};
};
